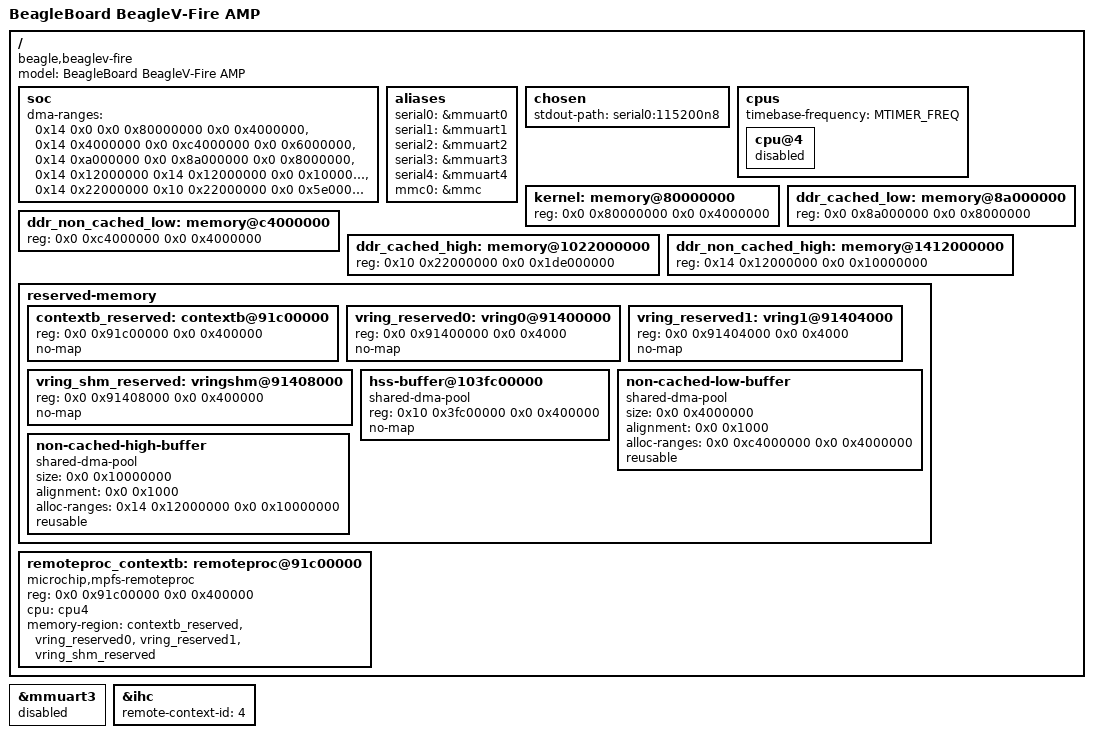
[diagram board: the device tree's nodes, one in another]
// SPDX-License-Identifier: (GPL-2.0 OR MIT)
/* Copyright (c) 2020-2021 Microchip Technology Inc */
/* BeagleV-Fire AMP Configuration */

/dts-v1/;

#include <dt-bindings/gpio/gpio.h>
#include "microchip/mpfs.dtsi"
#include "microchip/mpfs-beaglev-fire-fabric.dtsi"

/* Clock frequency (in Hz) of MTIMER */
#define MTIMER_FREQ		1000000

/ {
	#address-cells = <2>;
	#size-cells = <2>;
	model = "BeagleBoard BeagleV-Fire AMP";
	compatible = "beagle,beaglev-fire", "microchip,mpfs";

	soc {
		dma-ranges = <0x14 0x0 0x0 0x80000000 0x0 0x4000000>,
			     <0x14 0x4000000 0x0 0xc4000000 0x0 0x6000000>,
			     <0x14 0xa000000 0x0 0x8a000000 0x0 0x8000000>,
			     <0x14 0x12000000 0x14 0x12000000 0x0 0x10000000>,
			     <0x14 0x22000000 0x10 0x22000000 0x0 0x5e000000>;
	};

	aliases {
		serial0 = &mmuart0;
		serial1 = &mmuart1;
		serial2 = &mmuart2;
		serial3 = &mmuart3;
		serial4 = &mmuart4;
		mmc0 = &mmc;
	};

	chosen {
		stdout-path = "serial0:115200n8";
	};

	cpus {
		timebase-frequency = <MTIMER_FREQ>;
		
		/* AMP Configuration: Disable CPU4 for Linux, FreeRTOS will use it */
		cpu@4 {
			status = "disabled";
		};
	};

	kernel: memory@80000000 {
		device_type = "memory";
		reg = <0x0 0x80000000 0x0 0x4000000>;
	};

	ddr_cached_low: memory@8a000000 {
		device_type = "memory";
		reg = <0x0 0x8a000000 0x0 0x8000000>;
	};

	ddr_non_cached_low: memory@c4000000 {
		device_type = "memory";
		reg = <0x0 0xc4000000 0x0 0x4000000>;
	};

	ddr_cached_high: memory@1022000000 {
		device_type = "memory";
		reg = <0x10 0x22000000 0x0 0x1de000000>;
	};

	ddr_non_cached_high: memory@1412000000 {
		device_type = "memory";
		reg = <0x14 0x12000000 0x0 0x10000000>;
	};

	reserved-memory {
		#address-cells = <2>;
		#size-cells = <2>;
		ranges;

		/* AMP Memory regions for FreeRTOS context */
		contextb_reserved: contextb@91c00000 {
			reg = <0x0 0x91c00000 0x0 0x400000>;
			no-map;
		};

		/* Virtual ring buffers for RPMSG */
		vring_reserved0: vring0@91400000 {
			reg = <0x0 0x91400000 0x0 0x4000>;
			no-map;
		};

		vring_reserved1: vring1@91404000 {
			reg = <0x0 0x91404000 0x0 0x4000>;
			no-map;
		};

		/* Shared memory buffer */
		vring_shm_reserved: vringshm@91408000 {
			reg = <0x0 0x91408000 0x0 0x400000>;
			no-map;
		};

		hss-buffer@103fc00000 {
			compatible = "shared-dma-pool";
			reg = <0x10 0x3fc00000 0x0 0x400000>;
			no-map;
		};

		non-cached-low-buffer {
			compatible = "shared-dma-pool";
			size = <0x0 0x4000000>;
			alignment = <0x0 0x1000>;
			alloc-ranges = <0x0 0xc4000000 0x0 0x4000000>;
			reusable;
		};

		non-cached-high-buffer {
			compatible = "shared-dma-pool";
			size = <0x0 0x10000000>;
			alignment = <0x0 0x1000>;
			alloc-ranges = <0x14 0x12000000 0x0 0x10000000>;
			reusable;
		};
	};

	/* RemoteProc node for AMP context */
	remoteproc_contextb: remoteproc@91c00000 {
		compatible = "microchip,mpfs-remoteproc";
		reg = <0x0 0x91c00000 0x0 0x400000>;
		#address-cells = <2>;
		#size-cells = <2>;
		ranges;

		cpu = <&cpu4>;
		memory-region = <&contextb_reserved>, <&vring_reserved0>,
				<&vring_reserved1>, <&vring_shm_reserved>;
	};
};

/* UART3 disabled for Linux (used by FreeRTOS context) */
&mmuart3 {
	status = "disabled";
};

/* IHC (Inter-Hart Communication) for AMP */
&ihc {
	remote-context-id = <4>;
	status = "okay";
};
